# STM32L021xx register map
File version: 1.0
Registers are 32-bit, read-write, reset 0x0 unless marked. A register's access mark holds for its fields unless they carry their own. Offsets are from the block's base; [hi:lo] are bit positions; {n}, {i} and the like mark numbered series; 'fields as' and 'values as' point back to an identical list.

## COMP12_COMMON
Base 0x40010018; alternate view of COMP1
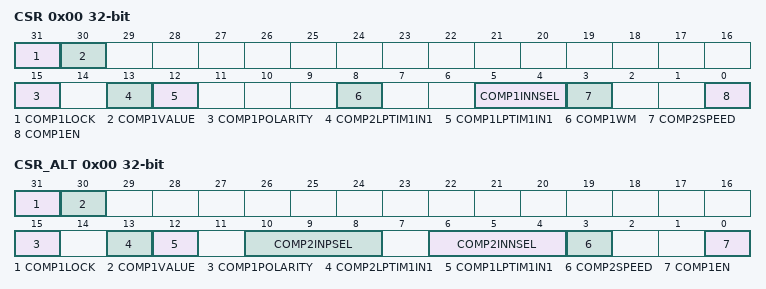
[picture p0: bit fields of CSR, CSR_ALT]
0x00 CSR — COMP control and status register, used for bits common to several COMP instances
  [31] COMP1LOCK
  [30] COMP1VALUE — COMP1 output level
  [15] COMP1POLARITY — COMP1 output polarity
  [13] COMP2LPTIM1IN1 — COMP2 LPTIM1 IN1 connection
  [12] COMP1LPTIM1IN1 — COMP1 LPTIM1 IN1 connection
  [8] COMP1WM — Comparators window mode enable
    0=DISABLE (Window mode disable: Comparators 1 and 2 are independent); 1=COMP1_INPUT_PLUS_COMMON (Window mode enable: Comparators instances pair COMP1 and COMP2 have their input plus connected together. The common input is COMP1 input plus (COMP2 input plus is no more accessible).)
  [5:4] COMP1INNSEL — COMP1 inverting input select
  [3] COMP2SPEED — COMP2 power mode
    1=MEDIUMSPEED (COMP power mode to fast speed (specific to COMP instance: COMP2)); 0=ULTRALOWPOWER (COMP power mode to low speed (specific to COMP instance: COMP2))
  [0] COMP1EN — COMP1 enable
0x00 CSR_ALT (alternate view of CSR) — COMP control and status register, used for bits common to several COMP instances
  [31] COMP1LOCK
  [30] COMP1VALUE — COMP1 output level
  [15] COMP1POLARITY — COMP1 output polarity
  [13] COMP2LPTIM1IN1 — COMP2 LPTIM1 IN1 connection
  [12] COMP1LPTIM1IN1 — COMP1 LPTIM1 IN1 connection
  [10:8] COMP2INPSEL — COMPx non inverting input select
    0=IO1 (Comparator input plus connected to IO1 (pin PA1 for COMP1, pin PA3 for COMP2)); 1=IO2 (Comparator input plus connected to IO2 (pin PB4 for COMP2) (specific to COMP instance: COMP2)); 2=IO3 (Comparator input plus connected to IO3 (pin PA5 for COMP2) (specific to COMP instance: COMP2)); 3=IO4 (Comparator input plus connected to IO4 (pin PB6 for COMP2) (specific to COMP instance: COMP2)); 4=IO5 (Comparator input plus connected to IO5 (pin PB7 for COMP2) (specific to COMP instance: COMP2)); 5=IO6 (Comparator input plus connected to IO6 (pin PA7 for COMP2) (specific to COMP instance: COMP2) (Available only on devices STM32L0 category 1))
  [6:4] COMP2INNSEL — COMP2 inverting input select
    0=VREFINT (Comparator input minus connected to VrefInt (specifity of COMP2 related to path to enable via SYSCFG: refer to comment in function @ref LL_COMP_SetInputMinus() )); 1=IO1 (Comparator input minus connected to IO1 (pin PA0 for COMP1, pin PA2 for COMP2)); 2=DAC1_CH1 (Comparator input minus connected to DAC1 channel 1 (DAC_OUT1)); 3=DAC1_CH2 (Comparator input minus connected to DAC1 channel 2 (DAC_OUT2)); 4=MINUS_1_4VREFINT (Comparator input minus connected to 1/4 VrefInt (specifity of COMP2 related to path to enable via SYSCFG: refer to comment in function @ref LL_COMP_SetInputMinus() ) (specific to COMP instance: COMP2)); 5=MINUS_1_2VREFINT (Comparator input minus connected to 1/2 VrefInt (specifity of COMP2 related to path to enable via SYSCFG: refer to comment in function @ref LL_COMP_SetInputMinus() ) (specific to COMP instance: COMP2)); 6=MINUS_3_4VREFINT (Comparator input minus connected to 3/4 VrefInt (specifity of COMP2 related to path to enable via SYSCFG: refer to comment in function @ref LL_COMP_SetInputMinus() ) (specific to COMP instance: COMP2)); 7=IO2 (Comparator input minus connected to IO2 (pin PB3 for COMP2) (specific to COMP instance: COMP2))
  [3] COMP2SPEED — COMP2 power mode
    values as CSR.COMP2SPEED
  [0] COMP1EN — COMP1 enable

## EXTI — External Interrupt/Event Controller
Base 0x40010400
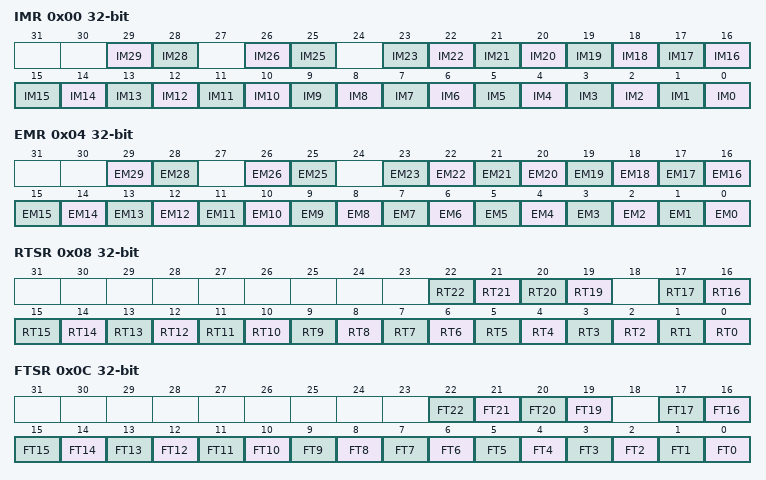
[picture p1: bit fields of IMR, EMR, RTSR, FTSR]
0x00 IMR — EXTI Interrupt mask register
  [29] IM29 — Interrupt Mask on line 29
  [28] IM28 — Interrupt Mask on line 28
  [26] IM26 — Interrupt Mask on line 26
  [25] IM25 — Interrupt Mask on line 25
  [n] IM{n} (n=0..23) — Interrupt Mask on line {n}
0x04 EMR — EXTI Event mask register
  [29] EM29 — Event Mask on line 29
  [28] EM28 — Event Mask on line 28
  [26] EM26 — Event Mask on line 26
  [25] EM25 — Event Mask on line 25
  [n] EM{n} (n=0..23) — Event Mask on line {n}
0x08 RTSR — EXTI Rising trigger selection register
  [n] RT{n} (n=19..22) — Rising trigger event configuration bit of line {n}
  [n] RT{n} (n=0..17) — Rising trigger event configuration bit of line {n}
0x0C FTSR — EXTI Falling trigger selection register
  [n] FT{n} (n=19..22) — Falling trigger event configuration bit of line {n}
  [n] FT{n} (n=0..17) — Falling trigger event configuration bit of line {n}
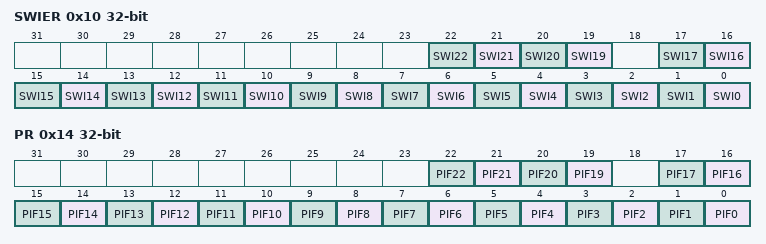
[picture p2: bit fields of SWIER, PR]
0x10 SWIER — EXTI Software interrupt event register
  [n] SWI{n} (n=19..22) — Software Interrupt on line {n}
  [n] SWI{n} (n=0..17) — Software Interrupt on line {n}
0x14 PR — EXTI Pending register
  [n] PIF{n} (n=19..22) — Pending bit {n}
  [n] PIF{n} (n=0..17) — Pending bit {n}
